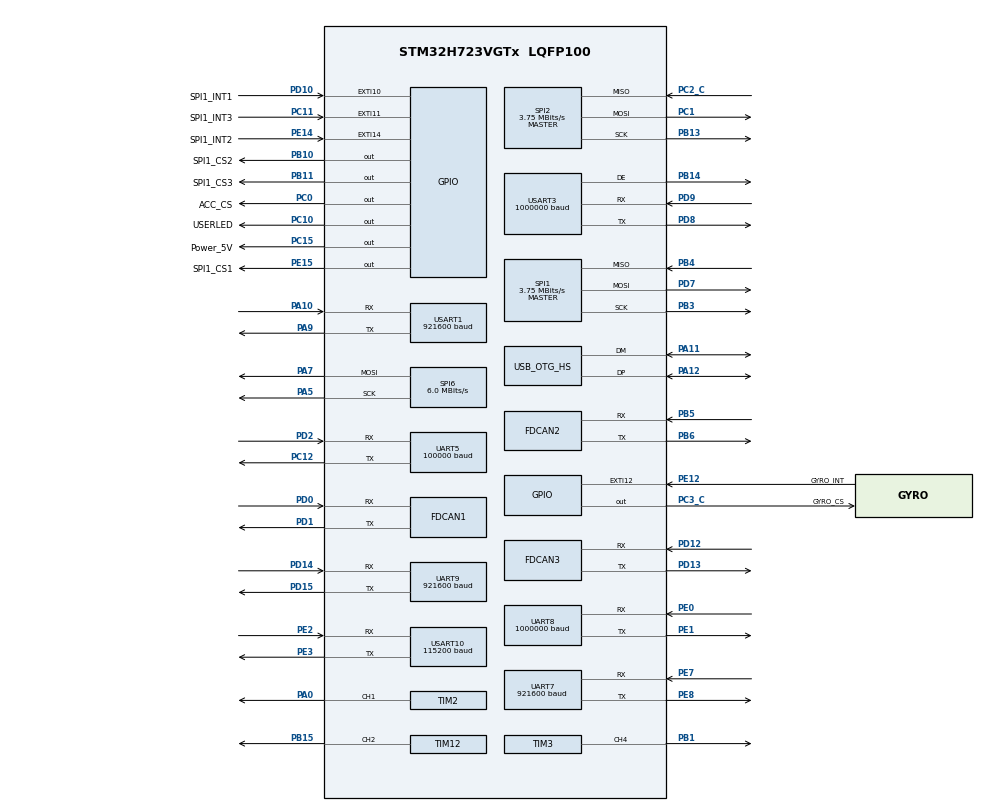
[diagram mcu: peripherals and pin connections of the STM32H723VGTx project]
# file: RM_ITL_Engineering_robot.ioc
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CORTEX_M7.AccessPermission-Cortex_Memory_Protection_Unit_Region0_Settings=MPU_REGION_FULL_ACCESS
CORTEX_M7.BaseAddress-Cortex_Memory_Protection_Unit_Region0_Settings=0x24000000
CORTEX_M7.CPU_DCache=Disabled
CORTEX_M7.CPU_ICache=Disabled
CORTEX_M7.Enable-Cortex_Memory_Protection_Unit_Region0_Settings=MPU_REGION_ENABLE
CORTEX_M7.IsBufferable-Cortex_Memory_Protection_Unit_Region0_Settings=MPU_ACCESS_BUFFERABLE
CORTEX_M7.IsCacheable-Cortex_Memory_Protection_Unit_Region0_Settings=MPU_ACCESS_CACHEABLE
CORTEX_M7.MPU_Control=__NULL
CORTEX_M7.Size-Cortex_Memory_Protection_Unit_Region0_Settings=MPU_REGION_SIZE_512KB
CORTEX_M7.TypeExtField-Cortex_Memory_Protection_Unit_Region0_Settings=MPU_TEX_LEVEL1
Dma.Request0=UART5_RX
Dma.Request1=USART1_RX
Dma.Request10=USART3_TX
Dma.Request11=UART9_RX
Dma.Request12=UART9_TX
Dma.Request13=UART8_RX
Dma.Request14=UART8_TX
Dma.Request15=TIM2_CH1
Dma.Request2=USART1_TX
Dma.Request3=SPI2_RX
Dma.Request4=SPI2_TX
Dma.Request5=UART7_RX
Dma.Request6=UART7_TX
Dma.Request7=USART10_RX
Dma.Request8=USART10_TX
Dma.Request9=USART3_RX
Dma.SPI2_RX.3.Direction=DMA_PERIPH_TO_MEMORY
Dma.SPI2_RX.3.EventEnable=DISABLE
Dma.SPI2_RX.3.FIFOMode=DMA_FIFOMODE_DISABLE
Dma.SPI2_RX.3.Instance=DMA1_Stream2
Dma.SPI2_RX.3.MemDataAlignment=DMA_MDATAALIGN_BYTE
Dma.SPI2_RX.3.MemInc=DMA_MINC_ENABLE
Dma.SPI2_RX.3.Mode=DMA_NORMAL
Dma.SPI2_RX.3.PeriphDataAlignment=DMA_PDATAALIGN_BYTE
Dma.SPI2_RX.3.PeriphInc=DMA_PINC_DISABLE
Dma.SPI2_RX.3.Polarity=HAL_DMAMUX_REQ_GEN_RISING
Dma.SPI2_RX.3.Priority=DMA_PRIORITY_VERY_HIGH
Dma.SPI2_RX.3.RequestNumber=1
Dma.SPI2_RX.3.SignalID=NONE
Dma.SPI2_RX.3.SyncEnable=DISABLE
Dma.SPI2_RX.3.SyncPolarity=HAL_DMAMUX_SYNC_NO_EVENT
Dma.SPI2_RX.3.SyncRequestNumber=1
Dma.SPI2_RX.3.SyncSignalID=NONE
Dma.SPI2_TX.4.Direction=DMA_MEMORY_TO_PERIPH
Dma.SPI2_TX.4.EventEnable=DISABLE
Dma.SPI2_TX.4.FIFOMode=DMA_FIFOMODE_DISABLE
Dma.SPI2_TX.4.Instance=DMA1_Stream3
Dma.SPI2_TX.4.MemDataAlignment=DMA_MDATAALIGN_BYTE
Dma.SPI2_TX.4.MemInc=DMA_MINC_ENABLE
Dma.SPI2_TX.4.Mode=DMA_NORMAL
Dma.SPI2_TX.4.PeriphDataAlignment=DMA_PDATAALIGN_BYTE
Dma.SPI2_TX.4.PeriphInc=DMA_PINC_DISABLE
Dma.SPI2_TX.4.Polarity=HAL_DMAMUX_REQ_GEN_RISING
Dma.SPI2_TX.4.Priority=DMA_PRIORITY_HIGH
Dma.SPI2_TX.4.RequestNumber=1
Dma.SPI2_TX.4.SignalID=NONE
Dma.SPI2_TX.4.SyncEnable=DISABLE
Dma.SPI2_TX.4.SyncPolarity=HAL_DMAMUX_SYNC_NO_EVENT
Dma.SPI2_TX.4.SyncRequestNumber=1
Dma.SPI2_TX.4.SyncSignalID=NONE
Dma.TIM2_CH1.15.Direction=DMA_MEMORY_TO_PERIPH
Dma.TIM2_CH1.15.EventEnable=DISABLE
Dma.TIM2_CH1.15.FIFOMode=DMA_FIFOMODE_DISABLE
Dma.TIM2_CH1.15.Instance=DMA2_Stream7
Dma.TIM2_CH1.15.MemDataAlignment=DMA_MDATAALIGN_HALFWORD
Dma.TIM2_CH1.15.MemInc=DMA_MINC_ENABLE
Dma.TIM2_CH1.15.Mode=DMA_NORMAL
Dma.TIM2_CH1.15.PeriphDataAlignment=DMA_PDATAALIGN_HALFWORD
Dma.TIM2_CH1.15.PeriphInc=DMA_PINC_DISABLE
Dma.TIM2_CH1.15.Polarity=HAL_DMAMUX_REQ_GEN_RISING
Dma.TIM2_CH1.15.Priority=DMA_PRIORITY_LOW
Dma.TIM2_CH1.15.RequestNumber=1
Dma.TIM2_CH1.15.SignalID=NONE
Dma.TIM2_CH1.15.SyncEnable=DISABLE
Dma.TIM2_CH1.15.SyncPolarity=HAL_DMAMUX_SYNC_NO_EVENT
Dma.TIM2_CH1.15.SyncRequestNumber=1
Dma.TIM2_CH1.15.SyncSignalID=NONE
Dma.UART5_RX.0.Direction=DMA_PERIPH_TO_MEMORY
Dma.UART5_RX.0.EventEnable=DISABLE
Dma.UART5_RX.0.FIFOMode=DMA_FIFOMODE_DISABLE
Dma.UART5_RX.0.Instance=DMA1_Stream5
Dma.UART5_RX.0.MemDataAlignment=DMA_MDATAALIGN_BYTE
Dma.UART5_RX.0.MemInc=DMA_MINC_ENABLE
Dma.UART5_RX.0.Mode=DMA_NORMAL
Dma.UART5_RX.0.PeriphDataAlignment=DMA_PDATAALIGN_BYTE
Dma.UART5_RX.0.PeriphInc=DMA_PINC_DISABLE
Dma.UART5_RX.0.Polarity=HAL_DMAMUX_REQ_GEN_RISING
Dma.UART5_RX.0.Priority=DMA_PRIORITY_LOW
Dma.UART5_RX.0.RequestNumber=1
Dma.UART5_RX.0.SignalID=NONE
Dma.UART5_RX.0.SyncEnable=DISABLE
Dma.UART5_RX.0.SyncPolarity=HAL_DMAMUX_SYNC_NO_EVENT
Dma.UART5_RX.0.SyncRequestNumber=1
Dma.UART5_RX.0.SyncSignalID=NONE
Dma.UART7_RX.5.Direction=DMA_PERIPH_TO_MEMORY
Dma.UART7_RX.5.EventEnable=DISABLE
Dma.UART7_RX.5.FIFOMode=DMA_FIFOMODE_DISABLE
Dma.UART7_RX.5.Instance=DMA1_Stream7
Dma.UART7_RX.5.MemDataAlignment=DMA_MDATAALIGN_BYTE
Dma.UART7_RX.5.MemInc=DMA_MINC_ENABLE
Dma.UART7_RX.5.Mode=DMA_NORMAL
Dma.UART7_RX.5.PeriphDataAlignment=DMA_PDATAALIGN_BYTE
Dma.UART7_RX.5.PeriphInc=DMA_PINC_DISABLE
Dma.UART7_RX.5.Polarity=HAL_DMAMUX_REQ_GEN_RISING
Dma.UART7_RX.5.Priority=DMA_PRIORITY_LOW
Dma.UART7_RX.5.RequestNumber=1
Dma.UART7_RX.5.SignalID=NONE
Dma.UART7_RX.5.SyncEnable=DISABLE
Dma.UART7_RX.5.SyncPolarity=HAL_DMAMUX_SYNC_NO_EVENT
Dma.UART7_RX.5.SyncRequestNumber=1
Dma.UART7_RX.5.SyncSignalID=NONE
Dma.UART7_TX.6.Direction=DMA_MEMORY_TO_PERIPH
Dma.UART7_TX.6.EventEnable=DISABLE
Dma.UART7_TX.6.FIFOMode=DMA_FIFOMODE_DISABLE
Dma.UART7_TX.6.Instance=DMA2_Stream0
Dma.UART7_TX.6.MemDataAlignment=DMA_MDATAALIGN_BYTE
Dma.UART7_TX.6.MemInc=DMA_MINC_ENABLE
Dma.UART7_TX.6.Mode=DMA_NORMAL
Dma.UART7_TX.6.PeriphDataAlignment=DMA_PDATAALIGN_BYTE
Dma.UART7_TX.6.PeriphInc=DMA_PINC_DISABLE
Dma.UART7_TX.6.Polarity=HAL_DMAMUX_REQ_GEN_RISING
Dma.UART7_TX.6.Priority=DMA_PRIORITY_LOW
Dma.UART7_TX.6.RequestNumber=1
Dma.UART7_TX.6.SignalID=NONE
Dma.UART7_TX.6.SyncEnable=DISABLE
Dma.UART7_TX.6.SyncPolarity=HAL_DMAMUX_SYNC_NO_EVENT
Dma.UART7_TX.6.SyncRequestNumber=1
Dma.UART7_TX.6.SyncSignalID=NONE
Dma.UART8_RX.13.Direction=DMA_PERIPH_TO_MEMORY
Dma.UART8_RX.13.EventEnable=DISABLE
Dma.UART8_RX.13.FIFOMode=DMA_FIFOMODE_DISABLE
Dma.UART8_RX.13.Instance=DMA2_Stream5
Dma.UART8_RX.13.MemDataAlignment=DMA_MDATAALIGN_BYTE
Dma.UART8_RX.13.MemInc=DMA_MINC_ENABLE
Dma.UART8_RX.13.Mode=DMA_NORMAL
Dma.UART8_RX.13.PeriphDataAlignment=DMA_PDATAALIGN_BYTE
Dma.UART8_RX.13.PeriphInc=DMA_PINC_DISABLE
Dma.UART8_RX.13.Polarity=HAL_DMAMUX_REQ_GEN_RISING
Dma.UART8_RX.13.Priority=DMA_PRIORITY_LOW
Dma.UART8_RX.13.RequestNumber=1
Dma.UART8_RX.13.SignalID=NONE
Dma.UART8_RX.13.SyncEnable=DISABLE
Dma.UART8_RX.13.SyncPolarity=HAL_DMAMUX_SYNC_NO_EVENT
Dma.UART8_RX.13.SyncRequestNumber=1
Dma.UART8_RX.13.SyncSignalID=NONE
Dma.UART8_TX.14.Direction=DMA_MEMORY_TO_PERIPH
Dma.UART8_TX.14.EventEnable=DISABLE
Dma.UART8_TX.14.FIFOMode=DMA_FIFOMODE_DISABLE
Dma.UART8_TX.14.Instance=DMA2_Stream6
Dma.UART8_TX.14.MemDataAlignment=DMA_MDATAALIGN_BYTE
Dma.UART8_TX.14.MemInc=DMA_MINC_ENABLE
Dma.UART8_TX.14.Mode=DMA_NORMAL
Dma.UART8_TX.14.PeriphDataAlignment=DMA_PDATAALIGN_BYTE
Dma.UART8_TX.14.PeriphInc=DMA_PINC_DISABLE
Dma.UART8_TX.14.Polarity=HAL_DMAMUX_REQ_GEN_RISING
Dma.UART8_TX.14.Priority=DMA_PRIORITY_LOW
Dma.UART8_TX.14.RequestNumber=1
Dma.UART8_TX.14.SignalID=NONE
Dma.UART8_TX.14.SyncEnable=DISABLE
Dma.UART8_TX.14.SyncPolarity=HAL_DMAMUX_SYNC_NO_EVENT
Dma.UART8_TX.14.SyncRequestNumber=1
Dma.UART8_TX.14.SyncSignalID=NONE
Dma.UART9_RX.11.Direction=DMA_PERIPH_TO_MEMORY
Dma.UART9_RX.11.EventEnable=DISABLE
Dma.UART9_RX.11.FIFOMode=DMA_FIFOMODE_DISABLE
Dma.UART9_RX.11.Instance=DMA1_Stream6
Dma.UART9_RX.11.MemDataAlignment=DMA_MDATAALIGN_BYTE
Dma.UART9_RX.11.MemInc=DMA_MINC_ENABLE
Dma.UART9_RX.11.Mode=DMA_NORMAL
Dma.UART9_RX.11.PeriphDataAlignment=DMA_PDATAALIGN_BYTE
Dma.UART9_RX.11.PeriphInc=DMA_PINC_DISABLE
Dma.UART9_RX.11.Polarity=HAL_DMAMUX_REQ_GEN_RISING
Dma.UART9_RX.11.Priority=DMA_PRIORITY_LOW
Dma.UART9_RX.11.RequestNumber=1
Dma.UART9_RX.11.SignalID=NONE
Dma.UART9_RX.11.SyncEnable=DISABLE
Dma.UART9_RX.11.SyncPolarity=HAL_DMAMUX_SYNC_NO_EVENT
Dma.UART9_RX.11.SyncRequestNumber=1
Dma.UART9_RX.11.SyncSignalID=NONE
Dma.UART9_TX.12.Direction=DMA_MEMORY_TO_PERIPH
Dma.UART9_TX.12.EventEnable=DISABLE
Dma.UART9_TX.12.FIFOMode=DMA_FIFOMODE_DISABLE
Dma.UART9_TX.12.Instance=DMA1_Stream4
Dma.UART9_TX.12.MemDataAlignment=DMA_MDATAALIGN_BYTE
Dma.UART9_TX.12.MemInc=DMA_MINC_ENABLE
Dma.UART9_TX.12.Mode=DMA_NORMAL
Dma.UART9_TX.12.PeriphDataAlignment=DMA_PDATAALIGN_BYTE
Dma.UART9_TX.12.PeriphInc=DMA_PINC_DISABLE
Dma.UART9_TX.12.Polarity=HAL_DMAMUX_REQ_GEN_RISING
Dma.UART9_TX.12.Priority=DMA_PRIORITY_LOW
Dma.UART9_TX.12.RequestNumber=1
Dma.UART9_TX.12.SignalID=NONE
Dma.UART9_TX.12.SyncEnable=DISABLE
Dma.UART9_TX.12.SyncPolarity=HAL_DMAMUX_SYNC_NO_EVENT
Dma.UART9_TX.12.SyncRequestNumber=1
Dma.UART9_TX.12.SyncSignalID=NONE
Dma.USART10_RX.7.Direction=DMA_PERIPH_TO_MEMORY
Dma.USART10_RX.7.EventEnable=DISABLE
Dma.USART10_RX.7.FIFOMode=DMA_FIFOMODE_DISABLE
Dma.USART10_RX.7.Instance=DMA2_Stream1
Dma.USART10_RX.7.MemDataAlignment=DMA_MDATAALIGN_BYTE
Dma.USART10_RX.7.MemInc=DMA_MINC_ENABLE
Dma.USART10_RX.7.Mode=DMA_NORMAL
Dma.USART10_RX.7.PeriphDataAlignment=DMA_PDATAALIGN_BYTE
Dma.USART10_RX.7.PeriphInc=DMA_PINC_DISABLE
Dma.USART10_RX.7.Polarity=HAL_DMAMUX_REQ_GEN_RISING
Dma.USART10_RX.7.Priority=DMA_PRIORITY_LOW
Dma.USART10_RX.7.RequestNumber=1
Dma.USART10_RX.7.SignalID=NONE
Dma.USART10_RX.7.SyncEnable=DISABLE
Dma.USART10_RX.7.SyncPolarity=HAL_DMAMUX_SYNC_NO_EVENT
Dma.USART10_RX.7.SyncRequestNumber=1
Dma.USART10_RX.7.SyncSignalID=NONE
Dma.USART10_TX.8.Direction=DMA_MEMORY_TO_PERIPH
Dma.USART10_TX.8.EventEnable=DISABLE
Dma.USART10_TX.8.FIFOMode=DMA_FIFOMODE_DISABLE
Dma.USART10_TX.8.Instance=DMA2_Stream2
Dma.USART10_TX.8.MemDataAlignment=DMA_MDATAALIGN_BYTE
Dma.USART10_TX.8.MemInc=DMA_MINC_ENABLE
Dma.USART10_TX.8.Mode=DMA_NORMAL
Dma.USART10_TX.8.PeriphDataAlignment=DMA_PDATAALIGN_BYTE
Dma.USART10_TX.8.PeriphInc=DMA_PINC_DISABLE
Dma.USART10_TX.8.Polarity=HAL_DMAMUX_REQ_GEN_RISING
Dma.USART10_TX.8.Priority=DMA_PRIORITY_LOW
Dma.USART10_TX.8.RequestNumber=1
Dma.USART10_TX.8.SignalID=NONE
Dma.USART10_TX.8.SyncEnable=DISABLE
Dma.USART10_TX.8.SyncPolarity=HAL_DMAMUX_SYNC_NO_EVENT
Dma.USART10_TX.8.SyncRequestNumber=1
Dma.USART10_TX.8.SyncSignalID=NONE
Dma.USART1_RX.1.Direction=DMA_PERIPH_TO_MEMORY
Dma.USART1_RX.1.EventEnable=DISABLE
Dma.USART1_RX.1.FIFOMode=DMA_FIFOMODE_DISABLE
Dma.USART1_RX.1.Instance=DMA1_Stream0
Dma.USART1_RX.1.MemDataAlignment=DMA_MDATAALIGN_BYTE
Dma.USART1_RX.1.MemInc=DMA_MINC_ENABLE
Dma.USART1_RX.1.Mode=DMA_NORMAL
Dma.USART1_RX.1.PeriphDataAlignment=DMA_PDATAALIGN_BYTE
Dma.USART1_RX.1.PeriphInc=DMA_PINC_DISABLE
Dma.USART1_RX.1.Polarity=HAL_DMAMUX_REQ_GEN_RISING
Dma.USART1_RX.1.Priority=DMA_PRIORITY_LOW
Dma.USART1_RX.1.RequestNumber=1
Dma.USART1_RX.1.SignalID=NONE
Dma.USART1_RX.1.SyncEnable=DISABLE
Dma.USART1_RX.1.SyncPolarity=HAL_DMAMUX_SYNC_NO_EVENT
Dma.USART1_RX.1.SyncRequestNumber=1
Dma.USART1_RX.1.SyncSignalID=NONE
Dma.USART1_TX.2.Direction=DMA_MEMORY_TO_PERIPH
Dma.USART1_TX.2.EventEnable=DISABLE
Dma.USART1_TX.2.FIFOMode=DMA_FIFOMODE_DISABLE
Dma.USART1_TX.2.Instance=DMA1_Stream1
Dma.USART1_TX.2.MemDataAlignment=DMA_MDATAALIGN_BYTE
Dma.USART1_TX.2.MemInc=DMA_MINC_ENABLE
Dma.USART1_TX.2.Mode=DMA_NORMAL
Dma.USART1_TX.2.PeriphDataAlignment=DMA_PDATAALIGN_BYTE
Dma.USART1_TX.2.PeriphInc=DMA_PINC_DISABLE
Dma.USART1_TX.2.Polarity=HAL_DMAMUX_REQ_GEN_RISING
Dma.USART1_TX.2.Priority=DMA_PRIORITY_LOW
Dma.USART1_TX.2.RequestNumber=1
Dma.USART1_TX.2.SignalID=NONE
Dma.USART1_TX.2.SyncEnable=DISABLE
Dma.USART1_TX.2.SyncPolarity=HAL_DMAMUX_SYNC_NO_EVENT
Dma.USART1_TX.2.SyncRequestNumber=1
Dma.USART1_TX.2.SyncSignalID=NONE
Dma.USART3_RX.9.Direction=DMA_PERIPH_TO_MEMORY
Dma.USART3_RX.9.EventEnable=DISABLE
Dma.USART3_RX.9.FIFOMode=DMA_FIFOMODE_DISABLE
Dma.USART3_RX.9.Instance=DMA2_Stream3
Dma.USART3_RX.9.MemDataAlignment=DMA_MDATAALIGN_BYTE
Dma.USART3_RX.9.MemInc=DMA_MINC_ENABLE
Dma.USART3_RX.9.Mode=DMA_NORMAL
Dma.USART3_RX.9.PeriphDataAlignment=DMA_PDATAALIGN_BYTE
Dma.USART3_RX.9.PeriphInc=DMA_PINC_DISABLE
Dma.USART3_RX.9.Polarity=HAL_DMAMUX_REQ_GEN_RISING
Dma.USART3_RX.9.Priority=DMA_PRIORITY_LOW
Dma.USART3_RX.9.RequestNumber=1
Dma.USART3_RX.9.SignalID=NONE
Dma.USART3_RX.9.SyncEnable=DISABLE
Dma.USART3_RX.9.SyncPolarity=HAL_DMAMUX_SYNC_NO_EVENT
Dma.USART3_RX.9.SyncRequestNumber=1
Dma.USART3_RX.9.SyncSignalID=NONE
Dma.USART3_TX.10.Direction=DMA_MEMORY_TO_PERIPH
Dma.USART3_TX.10.EventEnable=DISABLE
Dma.USART3_TX.10.FIFOMode=DMA_FIFOMODE_DISABLE
Dma.USART3_TX.10.Instance=DMA2_Stream4
Dma.USART3_TX.10.MemDataAlignment=DMA_MDATAALIGN_BYTE
Dma.USART3_TX.10.MemInc=DMA_MINC_ENABLE
Dma.USART3_TX.10.Mode=DMA_NORMAL
Dma.USART3_TX.10.PeriphDataAlignment=DMA_PDATAALIGN_BYTE
Dma.USART3_TX.10.PeriphInc=DMA_PINC_DISABLE
Dma.USART3_TX.10.Polarity=HAL_DMAMUX_REQ_GEN_RISING
Dma.USART3_TX.10.Priority=DMA_PRIORITY_LOW
Dma.USART3_TX.10.RequestNumber=1
Dma.USART3_TX.10.SignalID=NONE
Dma.USART3_TX.10.SyncEnable=DISABLE
Dma.USART3_TX.10.SyncPolarity=HAL_DMAMUX_SYNC_NO_EVENT
Dma.USART3_TX.10.SyncRequestNumber=1
Dma.USART3_TX.10.SyncSignalID=NONE
FDCAN1.AutoRetransmission=DISABLE
FDCAN1.CalculateBaudRateNominal=1000000
FDCAN1.CalculateTimeBitNominal=1000
FDCAN1.CalculateTimeQuantumNominal=25.0
FDCAN1.DataPrescaler=3
FDCAN1.DataSyncJumpWidth=10
FDCAN1.DataTimeSeg1=29
FDCAN1.DataTimeSeg2=10
FDCAN1.FrameFormat=FDCAN_FRAME_CLASSIC
FDCAN1.NominalPrescaler=3
FDCAN1.NominalSyncJumpWidth=10
FDCAN1.NominalTimeSeg1=29
FDCAN1.NominalTimeSeg2=10
FDCAN1.ProtocolException=ENABLE
FDCAN1.RxFifo0ElmtsNbr=32
FDCAN1.RxFifo1ElmtsNbr=32
FDCAN1.StdFiltersNbr=128
FDCAN1.TxFifoQueueElmtsNbr=32
FDCAN2.AutoRetransmission=DISABLE
FDCAN2.CalculateBaudRateNominal=1000000
FDCAN2.CalculateTimeBitNominal=1000
FDCAN2.CalculateTimeQuantumNominal=25.0
FDCAN2.DataPrescaler=3
FDCAN2.DataSyncJumpWidth=10
FDCAN2.DataTimeSeg1=29
FDCAN2.DataTimeSeg2=10
FDCAN2.FrameFormat=FDCAN_FRAME_CLASSIC
FDCAN2.MessageRAMOffset=854
FDCAN2.NominalPrescaler=3
FDCAN2.NominalSyncJumpWidth=10
FDCAN2.NominalTimeSeg1=29
FDCAN2.NominalTimeSeg2=10
FDCAN2.ProtocolException=ENABLE
FDCAN2.RxFifo0ElmtsNbr=32
FDCAN2.RxFifo1ElmtsNbr=32
FDCAN2.StdFiltersNbr=128
FDCAN2.TxFifoQueueElmtsNbr=32
FDCAN3.CalculateBaudRateNominal=1000000
FDCAN3.CalculateTimeBitNominal=1000
FDCAN3.CalculateTimeQuantumNominal=25.0
FDCAN3.DataPrescaler=3
FDCAN3.DataSyncJumpWidth=10
FDCAN3.DataTimeSeg1=29
FDCAN3.DataTimeSeg2=10
FDCAN3.MessageRAMOffset=1706
FDCAN3.NominalPrescaler=3
FDCAN3.NominalSyncJumpWidth=10
FDCAN3.NominalTimeSeg1=29
FDCAN3.NominalTimeSeg2=10
FDCAN3.ProtocolException=ENABLE
FDCAN3.RxFifo0ElmtsNbr=32
FDCAN3.RxFifo1ElmtsNbr=32
FDCAN3.StdFiltersNbr=128
FDCAN3.TxFifoQueueElmtsNbr=32
Mcu.Family=STM32H7
Mcu.Name=STM32H723VGTx
Mcu.Package=LQFP100
NVIC.DMA1_Stream0_IRQn=true\:0\:0\:false\:false\:true\:false\:true\:true
NVIC.DMA1_Stream1_IRQn=true\:0\:0\:false\:false\:true\:false\:true\:true
NVIC.DMA1_Stream2_IRQn=true\:0\:0\:false\:false\:true\:false\:true\:true
NVIC.DMA1_Stream3_IRQn=true\:0\:0\:false\:false\:true\:false\:true\:true
NVIC.DMA1_Stream4_IRQn=true\:0\:0\:false\:false\:true\:false\:true\:true
NVIC.DMA1_Stream5_IRQn=true\:0\:0\:false\:false\:true\:false\:true\:true
NVIC.DMA1_Stream6_IRQn=true\:0\:0\:false\:false\:true\:false\:true\:true
NVIC.DMA1_Stream7_IRQn=true\:0\:0\:false\:false\:true\:false\:true\:true
NVIC.DMA2_Stream0_IRQn=true\:0\:0\:false\:false\:true\:false\:true\:true
NVIC.DMA2_Stream1_IRQn=true\:0\:0\:false\:false\:true\:false\:true\:true
NVIC.DMA2_Stream2_IRQn=true\:0\:0\:false\:false\:true\:false\:true\:true
NVIC.DMA2_Stream3_IRQn=true\:0\:0\:false\:false\:true\:false\:true\:true
NVIC.DMA2_Stream4_IRQn=true\:0\:0\:false\:false\:true\:false\:true\:true
NVIC.DMA2_Stream5_IRQn=true\:0\:0\:false\:false\:true\:false\:true\:true
NVIC.DMA2_Stream6_IRQn=true\:0\:0\:false\:false\:true\:false\:true\:true
NVIC.DMA2_Stream7_IRQn=true\:0\:0\:false\:false\:true\:false\:true\:true
NVIC.EXTI15_10_IRQn=true\:0\:0\:false\:false\:true\:true\:true\:true
NVIC.FDCAN1_IT0_IRQn=true\:0\:0\:false\:false\:true\:true\:true\:true
NVIC.FDCAN1_IT1_IRQn=true\:0\:0\:false\:false\:true\:true\:true\:true
NVIC.FDCAN2_IT0_IRQn=true\:0\:0\:false\:false\:true\:true\:true\:true
NVIC.FDCAN2_IT1_IRQn=true\:0\:0\:false\:false\:true\:true\:true\:true
NVIC.FDCAN3_IT0_IRQn=true\:0\:0\:false\:false\:true\:true\:true\:true
NVIC.FDCAN3_IT1_IRQn=true\:0\:0\:false\:false\:true\:true\:true\:true
NVIC.FDCAN_CAL_IRQn=true\:0\:0\:false\:false\:true\:true\:true\:true
NVIC.OTG_HS_IRQn=true\:0\:0\:false\:false\:true\:false\:true\:true
NVIC.PriorityGroup=NVIC_PRIORITYGROUP_4
NVIC.SPI2_IRQn=true\:0\:0\:false\:false\:true\:false\:true\:true
NVIC.TIM23_IRQn=true\:15\:0\:true\:false\:true\:false\:true\:true
NVIC.TimeBase=TIM23_IRQn
NVIC.TimeBaseIP=TIM23
NVIC.UART5_IRQn=true\:0\:0\:false\:false\:true\:true\:true\:true
NVIC.UART7_IRQn=true\:0\:0\:false\:false\:true\:true\:true\:true
NVIC.UART8_IRQn=true\:0\:0\:false\:false\:true\:true\:true\:true
NVIC.UART9_IRQn=true\:0\:0\:false\:false\:true\:true\:true\:true
NVIC.USART10_IRQn=true\:0\:0\:false\:false\:true\:true\:true\:true
NVIC.USART1_IRQn=true\:0\:0\:false\:false\:true\:true\:true\:true
NVIC.USART3_IRQn=true\:0\:0\:false\:false\:true\:true\:true\:true
PA0.GPIO_Speed=GPIO_SPEED_FREQ_LOW
PA0.Signal=S_TIM2_CH1_ETR
PA10.Mode=Asynchronous
PA10.Signal=USART1_RX
PA11.Mode=Device_Only_FS
PA11.Signal=USB_OTG_HS_DM
PA12.Mode=Device_Only_FS
PA12.Signal=USB_OTG_HS_DP
PA13(JTMS/SWDIO).Mode=Serial_Wire
PA13(JTMS/SWDIO).Signal=DEBUG_JTMS-SWDIO
PA14(JTCK/SWCLK).Mode=Serial_Wire
PA14(JTCK/SWCLK).Signal=DEBUG_JTCK-SWCLK
PA5.Mode=TX_Only_Simplex_Unidirect_Master
PA5.Signal=SPI6_SCK
PA7.Mode=TX_Only_Simplex_Unidirect_Master
PA7.Signal=SPI6_MOSI
PA9.Mode=Asynchronous
PA9.Signal=USART1_TX
PB1.Signal=S_TIM3_CH4
PB10.GPIO_Label=SPI1_CS2
PB10.GPIO_Speed=GPIO_SPEED_FREQ_HIGH
PB10.PinState=GPIO_PIN_SET
PB10.Signal=GPIO_Output
PB11.GPIO_Label=SPI1_CS3
PB11.GPIO_Speed=GPIO_SPEED_FREQ_HIGH
PB11.PinState=GPIO_PIN_SET
PB11.Signal=GPIO_Output
PB13.GPIO_Speed=GPIO_SPEED_FREQ_VERY_HIGH
PB13.Mode=Full_Duplex_Master
PB13.Signal=SPI2_SCK
PB14.Mode=Hardware Flow Control (RS485)
PB14.Signal=USART3_DE
PB15.Signal=S_TIM12_CH2
PB3(JTDO/TRACESWO).GPIO_Speed=GPIO_SPEED_FREQ_HIGH
PB3(JTDO/TRACESWO).Mode=Full_Duplex_Master
PB3(JTDO/TRACESWO).Signal=SPI1_SCK
PB4(NJTRST).GPIO_Speed=GPIO_SPEED_FREQ_HIGH
PB4(NJTRST).Mode=Full_Duplex_Master
PB4(NJTRST).Signal=SPI1_MISO
PB5.Mode=FDCAN_Activate
PB5.Signal=FDCAN2_RX
PB6.Mode=FDCAN_Activate
PB6.Signal=FDCAN2_TX
PC0.GPIO_Label=ACC_CS
PC0.GPIO_Speed=GPIO_SPEED_FREQ_VERY_HIGH
PC0.PinState=GPIO_PIN_SET
PC0.Signal=GPIO_Output
PC1.GPIO_Speed=GPIO_SPEED_FREQ_VERY_HIGH
PC1.Mode=Full_Duplex_Master
PC1.Signal=SPI2_MOSI
PC10.GPIO_Label=USERLED
PC10.PinState=GPIO_PIN_SET
PC10.Signal=GPIO_Output
PC11.GPIO_Label=SPI1_INT3
PC11.GPIO_ModeDefaultEXTI=GPIO_MODE_IT_FALLING
PC11.GPIO_PuPd=GPIO_PULLUP
PC11.Signal=GPXTI11
PC12.Mode=Asynchronous
PC12.Signal=UART5_TX
PC15-OSC32_OUT.GPIO_Label=Power_5V
PC15-OSC32_OUT.PinState=GPIO_PIN_SET
PC15-OSC32_OUT.Signal=GPIO_Output
PC2_C.GPIO_Speed=GPIO_SPEED_FREQ_VERY_HIGH
PC2_C.Mode=Full_Duplex_Master
PC2_C.Signal=SPI2_MISO
PC3_C.GPIO_Label=GYRO_CS
PC3_C.GPIO_Speed=GPIO_SPEED_FREQ_VERY_HIGH
PC3_C.PinState=GPIO_PIN_SET
PC3_C.Signal=GPIO_Output
PD0.Mode=FDCAN_Activate
PD0.Signal=FDCAN1_RX
PD1.Mode=FDCAN_Activate
PD1.Signal=FDCAN1_TX
PD10.GPIO_Label=SPI1_INT1
PD10.GPIO_ModeDefaultEXTI=GPIO_MODE_IT_FALLING
PD10.GPIO_PuPd=GPIO_PULLUP
PD10.Signal=GPXTI10
PD12.Mode=FDCAN_Activate
PD12.Signal=FDCAN3_RX
PD13.Mode=FDCAN_Activate
PD13.Signal=FDCAN3_TX
PD14.Mode=Asynchronous
PD14.Signal=UART9_RX
PD15.Mode=Asynchronous
PD15.Signal=UART9_TX
PD2.Mode=Asynchronous
PD2.Signal=UART5_RX
PD5.Signal=USART2_TX
PD6.Signal=USART2_RX
PD7.GPIO_Speed=GPIO_SPEED_FREQ_HIGH
PD7.Mode=Full_Duplex_Master
PD7.Signal=SPI1_MOSI
PD8.Mode=Asynchronous
PD8.Signal=USART3_TX
PD9.Mode=Asynchronous
PD9.Signal=USART3_RX
PE0.Mode=Asynchronous
PE0.Signal=UART8_RX
PE1.Mode=Asynchronous
PE1.Signal=UART8_TX
PE12.GPIO_Label=GYRO_INT
PE12.Signal=GPXTI12
PE14.GPIO_Label=SPI1_INT2
PE14.GPIO_ModeDefaultEXTI=GPIO_MODE_IT_FALLING
PE14.GPIO_PuPd=GPIO_PULLUP
PE14.Signal=GPXTI14
PE15.GPIO_Label=SPI1_CS1
PE15.GPIO_Speed=GPIO_SPEED_FREQ_HIGH
PE15.PinState=GPIO_PIN_SET
PE15.Signal=GPIO_Output
PE2.Mode=Asynchronous
PE2.Signal=USART10_RX
PE3.Mode=Asynchronous
PE3.Signal=USART10_TX
PE7.Mode=Asynchronous
PE7.Signal=UART7_RX
PE8.Mode=Asynchronous
PE8.Signal=UART7_TX
PH0-OSC_IN.Mode=HSE-External-Oscillator
PH0-OSC_IN.Signal=RCC_OSC_IN
PH1-OSC_OUT.Mode=HSE-External-Oscillator
PH1-OSC_OUT.Signal=RCC_OSC_OUT
ProjectManager.HeapSize=0x2000
ProjectManager.StackSize=0x2000
ProjectManager.TargetToolchain=CMake
RCC.ADCFreq_Value=48375000
RCC.APB1Freq_Value=120000000
RCC.APB2Freq_Value=120000000
RCC.APB3Freq_Value=120000000
RCC.APB4Freq_Value=120000000
RCC.CortexFreq_Value=480000000
RCC.D1PPRE=RCC_APB3_DIV2
RCC.D2PPRE1=RCC_APB1_DIV2
RCC.D2PPRE2=RCC_APB2_DIV2
RCC.D3PPRE=RCC_APB4_DIV2
RCC.DIVM1=2
RCC.DIVN1=40
RCC.DIVP1=1
RCC.DIVQ1=4
RCC.HCLKFreq_Value=240000000
RCC.HPRE=RCC_HCLK_DIV2
RCC.HSE_VALUE=24000000
RCC.PLL2FRACN=0
RCC.PLL3FRACN=0
RCC.PLLFRACN=0
RCC.PLLSourceVirtual=RCC_PLLSOURCE_HSE
RCC.RNGCLockSelection=RCC_RNGCLKSOURCE_PLL
RCC.SPI6CLockSelection=RCC_SPI6CLKSOURCE_HSE
RCC.SYSCLKFreq_VALUE=480000000
RCC.SYSCLKSource=RCC_SYSCLKSOURCE_PLLCLK
RCC.USBCLockSelection=RCC_USBCLKSOURCE_HSI48
RCC.USBFreq_Value=48000000
SH.S_TIM12_CH2.0=TIM12_CH2,PWM Generation2 CH2
SH.S_TIM2_CH1_ETR.0=TIM2_CH1,PWM Generation1 CH1
SH.S_TIM3_CH4.0=TIM3_CH4,PWM Generation4 CH4
SPI1.BaudRatePrescaler=SPI_BAUDRATEPRESCALER_32
SPI1.CalculateBaudRate=3.75 MBits/s
SPI1.DataSize=SPI_DATASIZE_8BIT
SPI1.Direction=SPI_DIRECTION_2LINES
SPI1.Mode=SPI_MODE_MASTER
SPI1.NSSPMode=SPI_NSS_PULSE_DISABLE
SPI1.VirtualType=VM_MASTER
SPI2.BaudRatePrescaler=SPI_BAUDRATEPRESCALER_32
SPI2.CLKPhase=SPI_PHASE_2EDGE
SPI2.CLKPolarity=SPI_POLARITY_HIGH
SPI2.CalculateBaudRate=3.75 MBits/s
SPI2.DataSize=SPI_DATASIZE_8BIT
SPI2.Direction=SPI_DIRECTION_2LINES
SPI2.Mode=SPI_MODE_MASTER
SPI2.VirtualType=VM_MASTER
SPI6.BaudRatePrescaler=SPI_BAUDRATEPRESCALER_4
SPI6.CLKPhase=SPI_PHASE_2EDGE
SPI6.CalculateBaudRate=6.0 MBits/s
SPI6.DataSize=SPI_DATASIZE_8BIT
SPI6.Direction=SPI_DIRECTION_2LINES_TXONLY
SPI6.Mode=SPI_MODE_MASTER
SPI6.VirtualType=VM_MASTER
TIM12.Channel-PWM\ Generation2\ CH2=TIM_CHANNEL_2
TIM12.Period=2000-1
TIM12.Prescaler=24-1
TIM12.Pulse-PWM\ Generation2\ CH2=1000
TIM2.Channel-PWM\ Generation1\ CH1=TIM_CHANNEL_1
TIM2.OCFastMode_PWM-PWM\ Generation1\ CH1=TIM_OCFAST_DISABLE
TIM2.Period=299
TIM2.Pulse-PWM\ Generation1\ CH1=34
TIM3.AutoReloadPreload=TIM_AUTORELOAD_PRELOAD_ENABLE
TIM3.Channel-PWM\ Generation4\ CH4=TIM_CHANNEL_4
TIM3.Period=10000-1
TIM3.Prescaler=24-1
UART5.BaudRate=100000
UART5.Mode=MODE_RX
UART5.Parity=PARITY_EVEN
UART5.StopBits=UART_STOPBITS_2
UART5.WordLength=WORDLENGTH_9B
UART7.BaudRate=921600
UART8.BaudRate=1000000
UART9.BaudRate=921600
USART1.BaudRate=921600
USART1.VirtualMode-Asynchronous=VM_ASYNC
USART10.BaudRate=115200
USART10.VirtualMode=VM_ASYNC
USART3.BaudRate=1000000
USART3.VirtualMode-Asynchronous=VM_ASYNC
USART3.VirtualMode-Hardware\ Flow\ Control\ (RS485)=VM_ASYNC
USB_DEVICE.CLASS_NAME_HS=CDC
USB_DEVICE.VirtualMode=Cdc
USB_DEVICE.VirtualModeHS=Cdc_HS
USB_OTG_HS.VirtualMode-Device_Only_FS=Device_Only_FS
VP_MEMORYMAP_VS_MEMORYMAP.Mode=CurAppReg
VP_RNG_VS_RNG.Mode=RNG_Activate
VP_SYS_VS_tim23.Mode=TIM23
VP_USB_DEVICE_VS_USB_DEVICE_CDC_HS.Mode=CDC_HS
board=custom

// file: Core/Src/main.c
/* USER CODE BEGIN Header */
/**
  ******************************************************************************
  * @file           : main.c
  * @brief          : Main program body
  ******************************************************************************
  * @attention
  *
  * Copyright (c) 2025 STMicroelectronics.
  * All rights reserved.
  *
  * This software is licensed under terms that can be found in the LICENSE file
  * in the root directory of this software component.
  * If no LICENSE file comes with this software, it is provided AS-IS.
  *
  ******************************************************************************
  */
/* USER CODE END Header */
#include "main.h"
#include "dma.h"
#include "fdcan.h"
#include "memorymap.h"
#include "rng.h"
#include "spi.h"
#include "tim.h"
#include "usart.h"
#include "usb_device.h"
#include "gpio.h"

/* USER CODE BEGIN Includes */
#include "Init.h"
/* USER CODE END Includes */

void SystemClock_Config(void);

int main(void)
{

  /* MCU Configuration--------------------------------------------------------*/

  /* Reset of all peripherals, Initializes the Flash interface and the Systick. */
  HAL_Init();

  /* Configure the system clock */
  SystemClock_Config();

  /* Initialize all configured peripherals */
  MX_GPIO_Init();
  MX_DMA_Init();
  MX_SPI6_Init();
  MX_TIM12_Init();
  MX_FDCAN1_Init();
  MX_FDCAN2_Init();
  MX_UART5_Init();
  MX_USART1_UART_Init();
  MX_SPI2_Init();
  MX_FDCAN3_Init();
  MX_USB_DEVICE_Init();
  MX_TIM3_Init();
  MX_UART7_Init();
  MX_USART10_UART_Init();
  MX_USART3_UART_Init();
  MX_RNG_Init();
  MX_SPI1_Init();
  MX_UART9_Init();
  MX_UART8_Init();
  MX_TIM2_Init();
  /* USER CODE BEGIN 2 */
  Robot_Init();
  /* USER CODE END 2 */

  /* Infinite loop */
  while (1)
  {

    /* USER CODE BEGIN 3 */

    //data ++;
    //usart_vofa_send(&huart1, "%d, %d\r\n", Chaiss_3508[0].control_data->feedback->rotor_speed, 300);
    //usart_vofa_send(&huart1, "%d, %d\r\n", Chaiss_6020[0].control_data->feedback->rotor_speed, 100);
    //DWT_Delay(0.5);
    //DJI3508_Spd_mode(&hfdcan2, Chaiss_3508[0].control_data);
    //DJI3508_SpdClose_mode(&hfdcan2, Chaiss_3508[0].control_data);
    //DJI3508_SpdClose_mode2(&hfdcan2, Chaiss_3508[0].control_data);
    //DJI6020_Spd_mode(&hfdcan2, Chaiss_6020[0].control_data);
    //DJI6020_SpdClose_mode2(&hfdcan2, Chaiss_6020[0].control_data);
    //DJI6020_PosClose_mode(&hfdcan2, Chaiss_6020[0].control_data);
    //DJI6020_PosSpdClose_mode(&hfdcan2, Chaiss_6020[0].control_data);
    //DJI6020_PosSpdClose_MultiTurn(&hfdcan2, Chaiss_6020[0].control_data);
    //BMI088_read(gyro, accel, &temp);
    //DJI6020_PosClose_MultiTurn(&hfdcan2, Chaiss_6020[0].control_data);
    //DM_Pos_mode(&hfdcan1, 1, 6, 1);
    //DM_Spd_mode(&hfdcan1, 1, 1);
    //DJI6020_Spd_mode(&hfdcan2, 3300, 1300, 300, 300);
    //DJI3508_Spd_mode(&hfdcan2, 300, 300, 300, 300);
    //read_motor_rx(&hfdcan1, 1);
    //DWT_Delay(0.0002);
    //DWT_Delay(0.0003);
  }
  /* USER CODE END 3 */
}

void SystemClock_Config(void)
{
  RCC_OscInitTypeDef RCC_OscInitStruct = {0};
  RCC_ClkInitTypeDef RCC_ClkInitStruct = {0};

  /** Supply configuration update enable
  */
  HAL_PWREx_ConfigSupply(PWR_LDO_SUPPLY);

  /** Configure the main internal regulator output voltage
  */
  __HAL_PWR_VOLTAGESCALING_CONFIG(PWR_REGULATOR_VOLTAGE_SCALE0);

  while(!__HAL_PWR_GET_FLAG(PWR_FLAG_VOSRDY)) {}

  /** Initializes the RCC Oscillators according to the specified parameters
  * in the RCC_OscInitTypeDef structure.
  */
  RCC_OscInitStruct.OscillatorType = RCC_OSCILLATORTYPE_HSI48|RCC_OSCILLATORTYPE_HSE;
  RCC_OscInitStruct.HSEState = RCC_HSE_ON;
  RCC_OscInitStruct.HSI48State = RCC_HSI48_ON;
  RCC_OscInitStruct.PLL.PLLState = RCC_PLL_ON;
  RCC_OscInitStruct.PLL.PLLSource = RCC_PLLSOURCE_HSE;
  RCC_OscInitStruct.PLL.PLLM = 2;
  RCC_OscInitStruct.PLL.PLLN = 40;
  RCC_OscInitStruct.PLL.PLLP = 1;
  RCC_OscInitStruct.PLL.PLLQ = 4;
  RCC_OscInitStruct.PLL.PLLR = 2;
  RCC_OscInitStruct.PLL.PLLRGE = RCC_PLL1VCIRANGE_3;
  RCC_OscInitStruct.PLL.PLLVCOSEL = RCC_PLL1VCOWIDE;
  RCC_OscInitStruct.PLL.PLLFRACN = 0;
  if (HAL_RCC_OscConfig(&RCC_OscInitStruct) != HAL_OK)
  {
    Error_Handler();
  }

  /** Initializes the CPU, AHB and APB buses clocks
  */
  RCC_ClkInitStruct.ClockType = RCC_CLOCKTYPE_HCLK|RCC_CLOCKTYPE_SYSCLK
                              |RCC_CLOCKTYPE_PCLK1|RCC_CLOCKTYPE_PCLK2
                              |RCC_CLOCKTYPE_D3PCLK1|RCC_CLOCKTYPE_D1PCLK1;
  RCC_ClkInitStruct.SYSCLKSource = RCC_SYSCLKSOURCE_PLLCLK;
  RCC_ClkInitStruct.SYSCLKDivider = RCC_SYSCLK_DIV1;
  RCC_ClkInitStruct.AHBCLKDivider = RCC_HCLK_DIV2;
  RCC_ClkInitStruct.APB3CLKDivider = RCC_APB3_DIV2;
  RCC_ClkInitStruct.APB1CLKDivider = RCC_APB1_DIV2;
  RCC_ClkInitStruct.APB2CLKDivider = RCC_APB2_DIV2;
  RCC_ClkInitStruct.APB4CLKDivider = RCC_APB4_DIV2;

  if (HAL_RCC_ClockConfig(&RCC_ClkInitStruct, FLASH_LATENCY_3) != HAL_OK)
  {
    Error_Handler();
  }
}

void HAL_TIM_PeriodElapsedCallback(TIM_HandleTypeDef *htim)
{
  if (htim->Instance == TIM23)
  {
    HAL_IncTick();
  }
}

void Error_Handler(void)
{
  __disable_irq();
  while (1)
  {
  }
}
